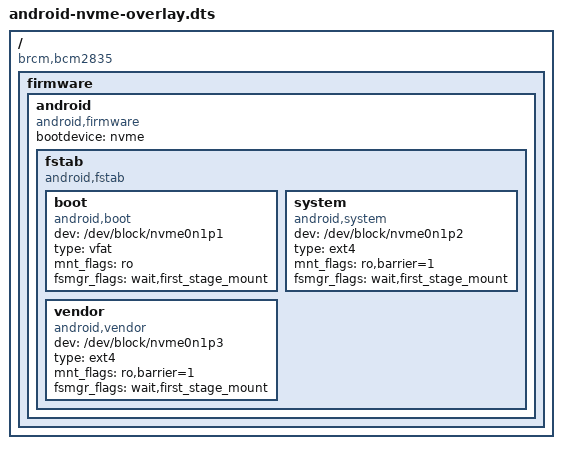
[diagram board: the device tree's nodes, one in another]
/dts-v1/;
/plugin/;
/ {
    compatible = "brcm,bcm2835";
    fragment@0 {
        target-path = "/";
        __overlay__ {
            firmware {
                android {
                    compatible = "android,firmware";
                    bootdevice = "nvme";
                    fstab {
                        compatible = "android,fstab";
                        boot {
                            compatible = "android,boot";
                            dev = "/dev/block/nvme0n1p1";
                            type = "vfat";
                            mnt_flags = "ro";
                            fsmgr_flags = "wait,first_stage_mount";
                        };
                        system {
                            compatible = "android,system";
                            dev = "/dev/block/nvme0n1p2";
                            type = "ext4";
                            mnt_flags = "ro,barrier=1";
                            fsmgr_flags = "wait,first_stage_mount";
                        };
                        vendor {
                            compatible = "android,vendor";
                            dev = "/dev/block/nvme0n1p3";
                            type = "ext4";
                            mnt_flags = "ro,barrier=1";
                            fsmgr_flags = "wait,first_stage_mount";
                        };
                    };
                };
            };
        };
    };
};
